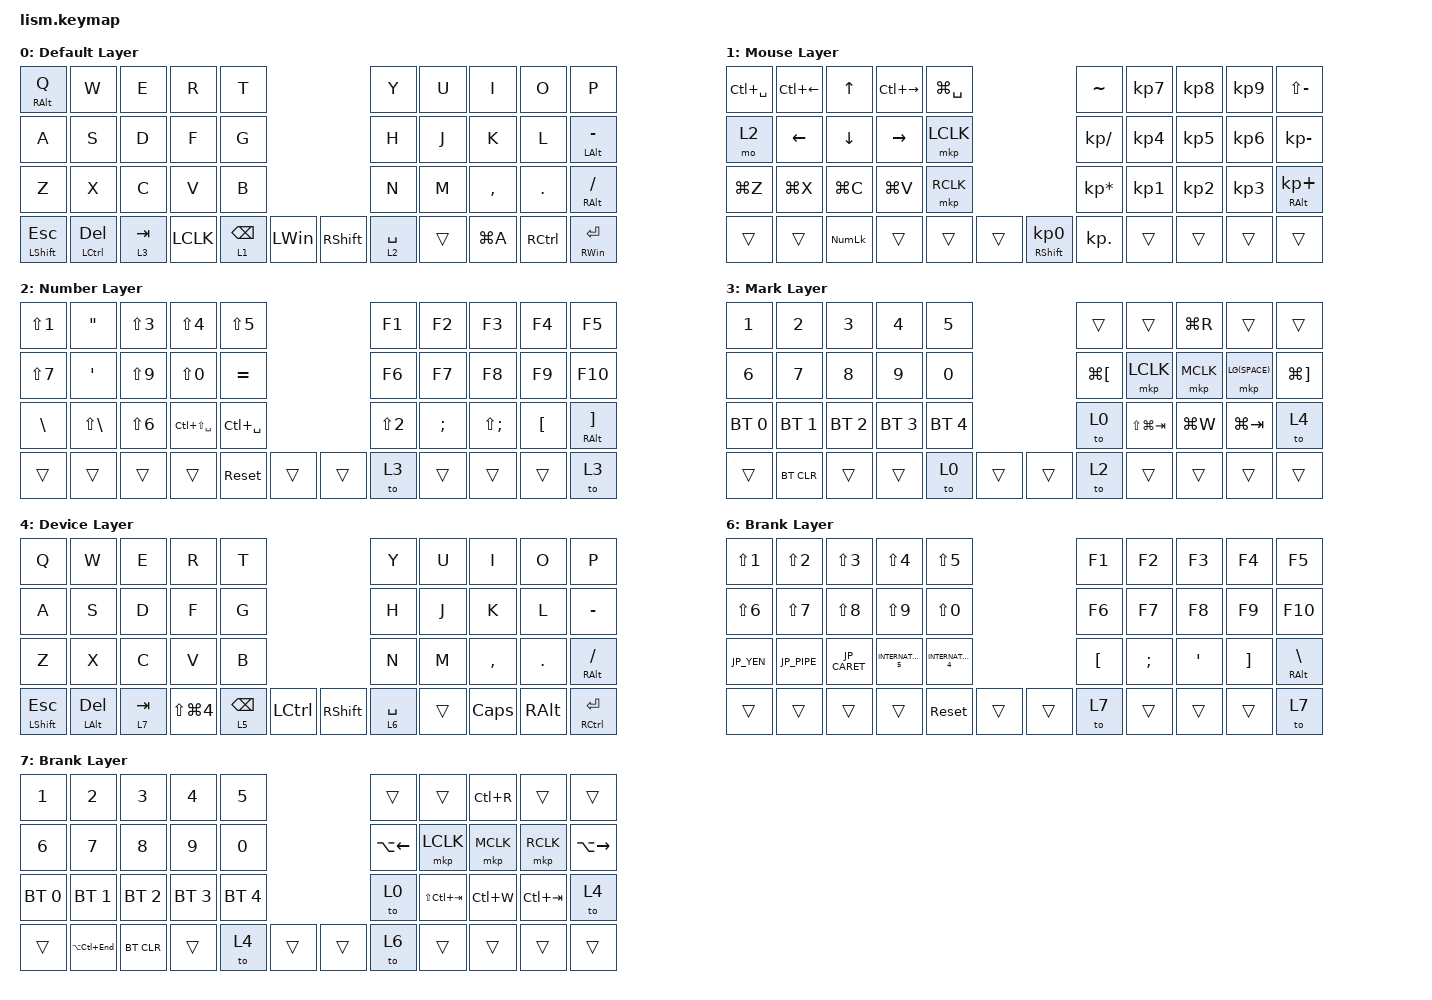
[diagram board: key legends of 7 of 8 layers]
#define ZMK_POINTING_DEFAULT_SCRL_VAL 200

#include <behaviors.dtsi>
#include <dt-bindings/zmk/bt.h>
#include <dt-bindings/zmk/keys.h>
#include <dt-bindings/zmk/pointing.h>
#include <dt-bindings/zmk/mouse.h>

&mt {
    tapping-term-ms = <300>;
    flavor = "balanced";
};

&lt {
    quick-tap-ms = <300>;
};


/ {
    macros {
        emoji: emoji_macro {
            compatible = "zmk,behavior-macro";
            label = "EMOJI";
            #binding-cells = <0>;
            bindings = 
                <&macro_press &kp CAPSLOCK>,
                <&macro_tap &kp E>,
                <&macro_release &kp CAPSLOCK>;
        };
    };

    behaviors {
        encoder_msc: sensor_rotate_msc {
            compatible = "zmk,behavior-sensor-rotate-var";
            #sensor-binding-cells = <2>;
            bindings = <&msc>, <&msc>;
            tap-ms = <20>;
        };

        encoder_kp: sensor_rotate_kp {
            compatible = "zmk,behavior-sensor-rotate-var";
            #sensor-binding-cells = <2>;
            bindings = <&kp>, <&kp>;
        };
    };

// OS設定を日本語キーボードのまま使用するための変換定義

#define JP_DQUOTE       AT                // "
#define JP_AMPERSAND    CARET             // &
#define JP_QUOTE        AMPERSAND         // '
#define JP_EQUAL        UNDER             // =
#define JP_CARET        EQUAL             // ^
#define JP_YEN          0x89              // ¥
#define JP_PLUS         COLON             // +
#define JP_TILDE        PLUS              // ~
#define JP_PIPE         LS(0x89)          // |
#define JP_AT           LEFT_BRACKET      // @
#define JP_COLON        SINGLE_QUOTE      // :
#define JP_ASTERISK     DOUBLE_QUOTES     // *
#define JP_BACKQUOTE    LEFT_BRACE        // `
#define JP_UNDERSCORE   LS(0x87)          // _
#define JP_LBRACKET     RIGHT_BRACKET     // [
#define JP_RBRACKET     BACKSLASH         // ]
#define JP_LPAREN       ASTERISK          // (
#define JP_RPAREN       LEFT_PARENTHESIS  // )
#define JP_LBRACE       RIGHT_BRACE       // {
#define JP_RBRACE       PIPE              // }
#define JP_KANA         LANGUAGE_1        // かな
#define JP_EISU         LANGUAGE_2        // 英数
#define JP_HANZEN       GRAVE             // 半角/全角

    keymap {
        compatible = "zmk,keymap";

        default_layer {
            display-name = "Default Layer";
            bindings = <
                &mt RALT Q         &kp W             &kp E         &kp R            &kp T                                          &kp Y        &kp U   &kp I        &kp O      &kp P
                &kp A              &kp S             &kp D         &kp F            &kp G                                          &kp H        &kp J   &kp K        &kp L      &mt LEFT_ALT MINUS
                &kp Z              &kp X             &kp C         &kp V            &kp B                                          &kp N        &kp M   &kp COMMA    &kp DOT    &mt RIGHT_ALT FSLH
                &mt LSHIFT ESCAPE  &mt LCTRL DELETE  &lt 3 TAB     &kp LCLK   &lt 1 BACKSPACE  &kp LEFT_WIN      &kp RSHIFT  &lt 2 SPACE  &trans  &kp LG(A)     &kp RCTRL  &mt RIGHT_WIN ENTER 
            >;
            sensor-bindings = <&encoder_msc SCRL_DOWN SCRL_UP>;
        };

        layer_1 {
            display-name = "Mouse Layer";
            bindings = <
                &kp LC(SPACE)  &kp LC(LEFT_ARROW)  &kp UP_ARROW    &kp LC(RIGHT)    &kp  LG(SPACE)                                  &kp TILDE        &kp KP_NUMBER_7  &kp KP_NUMBER_8  &kp KP_NUMBER_9  &kp LS(MINUS)
                &mo 2          &kp LEFT_ARROW      &kp DOWN_ARROW  &kp RIGHT_ARROW  &mkp LCLK                                       &kp KP_DIVIDE    &kp KP_NUMBER_4  &kp KP_NUMBER_5  &kp KP_NUMBER_6  &kp KP_MINUS
                &kp LG(Z)      &kp LG(X)           &kp LG(C)       &kp LG(V)        &mkp RCLK                                       &kp KP_ASTERISK  &kp KP_NUMBER_1  &kp KP_NUMBER_2  &kp KP_NUMBER_3  &mt RIGHT_ALT KP_PLUS
                &trans         &trans              &kp KP_NUMLOCK  &trans           &trans     &trans  &mt RIGHT_SHIFT KP_NUMBER_0  &kp KP_DOT       &trans           &trans           &trans           &trans
            >;
        };

        layer_2 {
            display-name = "Number Layer";
            bindings = <
                &kp LS(NUMBER_1)  &kp DOUBLE_QUOTES  &kp LS(N3)        &kp LS(N4)         &kp LS(N5)                     &kp F1      &kp F2    &kp F3             &kp F4            &kp F5
                &kp LS(N7)        &kp SINGLE_QUOTE   &kp LS(N9)        &kp LS(N0)         &kp EQUAL                      &kp F6      &kp F7    &kp F8             &kp F9            &kp F10
                &kp BACKSLASH     &kp LS(BACKSLASH)  &kp LS(NUMBER_6)  &kp LC(LS(SPACE))  &kp LC(SPACE)                  &kp LS(N2)  &kp SEMI  &kp LS(SEMICOLON)  &kp LEFT_BRACKET  &mt RIGHT_ALT RIGHT_BRACKET
                &trans            &trans             &trans            &trans             &sys_reset     &trans  &trans  &to 3       &trans    &trans             &trans            &to 3
            >;
            sensor-bindings = <&encoder_kp C_VOL_UP C_VOL_DN>;
        };

        layer_3 {
            display-name = "Mark Layer";
            bindings = <
                &kp N1        &kp N2        &kp N3        &kp N4        &kp N5                        &trans                &trans           &kp LG(R)  &trans       &trans
                &kp N6        &kp N7        &kp N8        &kp N9        &kp N0                        &kp LG(LEFT_BRACKET)  &mkp LCLK        &mkp MCLK  &mkp LG(SPACE)    &kp LG(RIGHT_BRACKET)
                &bt BT_SEL 0  &bt BT_SEL 1  &bt BT_SEL 2  &bt BT_SEL 3  &bt BT_SEL 4                  &to 0                 &kp LS(LG(TAB))  &kp LG(W)  &kp LG(TAB)  &to 4  
                &trans        &bt BT_CLR    &trans        &trans        &to 0         &trans  &trans  &to 2                 &trans           &trans     &trans       &trans
            >;
        };

        layer_4 {
            display-name = "Device Layer";
            bindings = <
                &kp Q              &kp W            &kp E              &kp R      &kp T                                   &kp Y        &kp U   &kp I      &kp O     &kp P
                &kp A              &kp S            &kp D              &kp F      &kp G                                   &kp H        &kp J   &kp K      &kp L     &kp MINUS
                &kp Z              &kp X            &kp C              &kp V      &kp B                                   &kp N        &kp M   &kp COMMA  &kp DOT   &mt RIGHT_ALT FSLH
                &mt LSHIFT ESCAPE  &mt LALT DELETE  &lt 7 TAB     &kp LS(LG(N4))  &lt 5 BACKSPACE  &kp LCTRL  &kp RSHIFT  &lt 6 SPACE  &trans  &kp CAPS     &kp RALT  &mt RCTRL ENTER
            >;
        };

        layer_5 {
            display-name = "Brank Layer";
            bindings = <
                &kp TILDE  &kp HOME        &kp UP_ARROW    &kp END          &mkp MCLK                                       &kp JP_TILDE     &kp KP_NUMBER_7  &kp KP_NUMBER_8  &kp KP_NUMBER_9  &kp JP_UNDERSCORE
                &mo 2      &kp LEFT_ARROW  &kp DOWN_ARROW  &kp RIGHT_ARROW  &mkp LCLK                                       &kp KP_DIVIDE    &kp KP_NUMBER_4  &kp KP_NUMBER_5  &kp KP_NUMBER_6  &kp KP_MINUS
                &kp LC(Z)  &kp LC(X)       &kp LC(C)       &kp LC(V)        &mkp RCLK                                       &kp KP_ASTERISK  &kp KP_NUMBER_1  &kp KP_NUMBER_2  &kp KP_NUMBER_3  &mt RIGHT_ALT KP_PLUS
                &trans     &trans          &kp KP_NUMLOCK  &trans           &trans    &mt RIGHT_SHIFT          KP_NUMBER_0  &kp KP_DOT       &trans           &trans           &trans           &trans
            >;
        };

        layer_6 {
            display-name = "Brank Layer";
            bindings = <
                &kp LS(NUMBER_1)  &kp LS(NUMBER_2)  &kp LS(N3)    &kp LS(N4)           &kp LS(N5)                           &kp F1    &kp F2    &kp F3    &kp F4    &kp F5
                &kp LS(N6)        &kp LS(N7)        &kp LS(N8)    &kp LS(N9)           &kp LS(N0)                           &kp F6    &kp F7    &kp F8    &kp F9    &kp F10
                &kp JP_YEN        &kp JP_PIPE       &kp JP_CARET  &kp INTERNATIONAL_5  &kp INTERNATIONAL_4                  &kp LBKT  &kp SEMI  &kp APOS  &kp RBKT  &mt RIGHT_ALT BSLH
                &trans            &trans            &trans        &trans               &sys_reset           &trans  &trans  &to 7     &trans    &trans    &trans    &to 7
            >;
        };

        layer_7 {
            display-name = "Brank Layer";
            bindings = <
                &kp N1        &kp N2           &kp N3        &kp N4        &kp N5                        &trans        &trans           &kp LC(R)  &trans       &trans
                &kp N6        &kp N7           &kp N8        &kp N9        &kp N0                        &kp LA(LEFT)  &mkp LCLK        &mkp MCLK  &mkp RCLK    &kp LA(RIGHT)
                &bt BT_SEL 0  &bt BT_SEL 1     &bt BT_SEL 2  &bt BT_SEL 3  &bt BT_SEL 4                  &to 0         &kp LS(LC(TAB))  &kp LC(W)  &kp LC(TAB)  &to 4
                &trans        &kp LA(LC(END))  &bt BT_CLR    &trans        &to 4         &trans  &trans  &to 6         &trans           &trans     &trans       &trans
            >;
        };
    };

};
